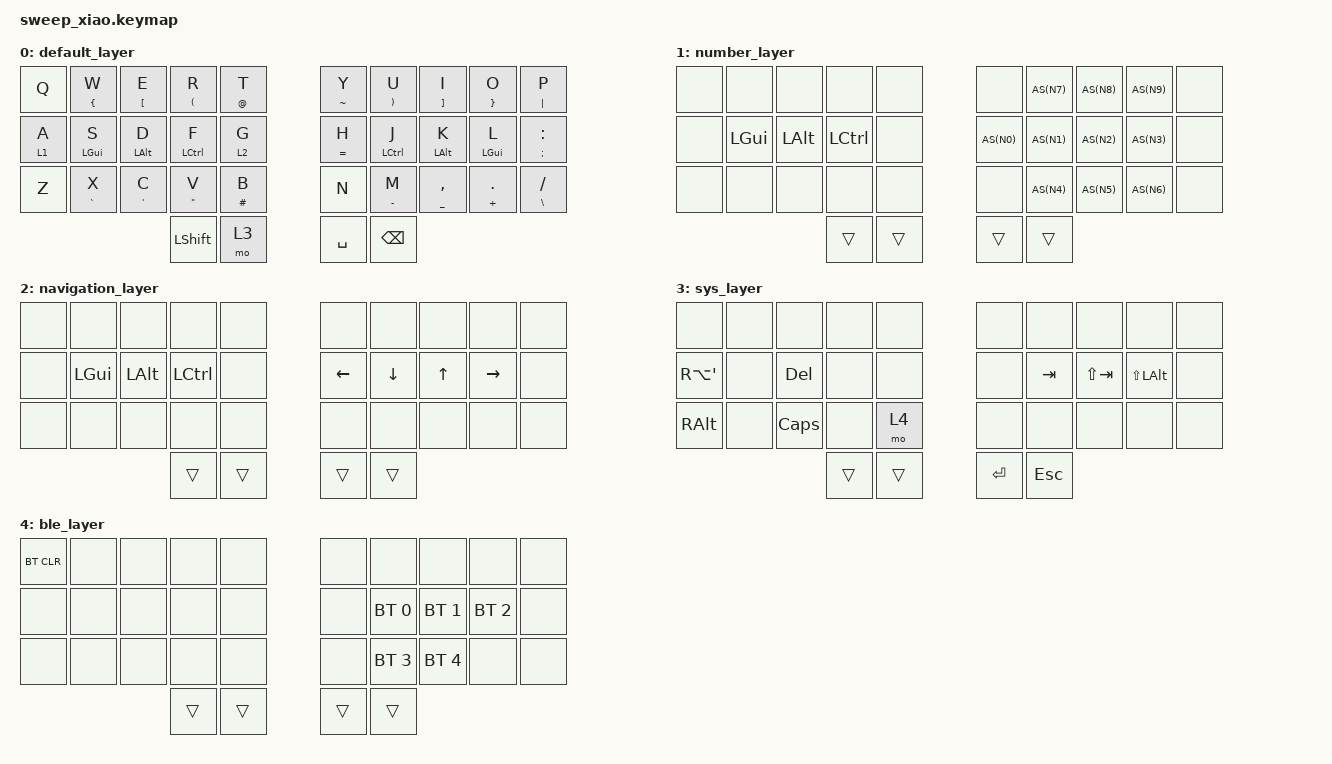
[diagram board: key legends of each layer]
#include <behaviors.dtsi>
#include <dt-bindings/zmk/keys.h>
#include <dt-bindings/zmk/bt.h>

#define AS(key) &ht LS(key) key


/ {
    behaviors {
        ht: hold_tap {
            label = "hold_tap";
            compatible = "zmk,behavior-hold-tap";
            #binding-cells = <2>;
            flavor = "tap-preferred";
            tapping-term-ms = <200>;
            quick-tap-ms = <200>;
            bindings = <&kp>, <&kp>;
        };
        hm: homerow_mods {
            label = "homerow_mods";
            compatible = "zmk,behavior-hold-tap";
            #binding-cells = <2>;
            flavor = "tap-preferred";
            tapping-term-ms = <200>;
            quick-tap-ms = <200>;
            require-prior-idle-ms = <150>;
            bindings = <&kp>, <&kp>;
        };
    };

    keymap {
        compatible = "zmk,keymap";
        default_layer {
            bindings = <
        //╭────────────┬────────────┬────────────┬────────────┬────────────╮   ╭────────────┬────────────┬────────────────┬─────────────┬──────────────╮
           &kp Q        &ht LBRC W   &ht LBKT E   &ht LPAR R   &ht AT T         &ht TILDE Y  &ht RPAR U   &ht RBKT I       &ht RBRC O    &ht PIPE P
        //├────────────┼────────────┼────────────┼────────────┼────────────┤   ├────────────┼────────────┼────────────────┼─────────────┼──────────────┤
           &lt 1 A      &hm LGUI S   &hm LALT D   &hm LCTRL F  &lt 2 G          &ht EQUAL H  &hm LCTRL J  &hm LALT K       &hm LGUI L    &ht SEMI COLON
        //├────────────┼────────────┼────────────┼────────────┼────────────┤   ├────────────┼────────────┼────────────────┼─────────────┼──────────────┤
           &kp Z        &ht GRAVE X  &ht SQT C    &ht DQT V    &ht HASH B       &kp N        &ht MINUS M  &ht UNDER COMMA  &ht PLUS DOT  &ht BSLH FSLH
        //╰────────────┴────────────┴────────────┼────────────┼────────────┤   ├────────────┼────────────┼────────────────┴─────────────┴──────────────╯
                                                  &kp LSHFT    &mo 3            &kp SPACE    &kp BSPC
        //                                       ╰────────────┴────────────╯   ╰────────────┴────────────╯
            >;
        };

        number_layer {
            bindings = <
        //╭────────────┬────────────┬────────────┬────────────┬────────────╮   ╭────────────┬────────────┬────────────┬────────────┬────────────╮
           &none        &none        &none        &none        &none            &none        AS(N7)       AS(N8)       AS(N9)       &none
        //├────────────┼────────────┼────────────┼────────────┼────────────┤   ├────────────┼────────────┼────────────┼────────────┼────────────┤
           &none        &kp LGUI     &kp LALT     &kp LCTRL    &none            AS(N0)       AS(N1)       AS(N2)       AS(N3)       &none
        //├────────────┼────────────┼────────────┼────────────┼────────────┤   ├────────────┼────────────┼────────────┼────────────┼────────────┤
           &none        &none        &none        &none        &none            &none        AS(N4)       AS(N5)       AS(N6)       &none
        //╰────────────┴────────────┴────────────┼────────────┼────────────┤   ├────────────┼────────────┼────────────┴────────────┴────────────╯
                                                  &trans       &trans           &trans       &trans
        //                                       ╰────────────┴────────────╯   ╰────────────┴────────────╯
            >;
        };

        navigation_layer {
            bindings = <
        //╭────────────┬────────────┬────────────┬────────────┬────────────╮   ╭────────────┬────────────┬────────────┬────────────┬────────────╮
           &none        &none        &none        &none        &none            &none        &none        &none        &none        &none
        //├────────────┼────────────┼────────────┼────────────┼────────────┤   ├────────────┼────────────┼────────────┼────────────┼────────────┤
           &none        &kp LGUI     &kp LALT     &kp LCTRL    &none            &kp LEFT     &kp DOWN     &kp UP       &kp RIGHT    &none
        //├────────────┼────────────┼────────────┼────────────┼────────────┤   ├────────────┼────────────┼────────────┼────────────┼────────────┤
           &none        &none        &none        &none        &none            &none        &none        &none        &none        &none
        //╰────────────┴────────────┴────────────┼────────────┼────────────┤   ├────────────┼────────────┼────────────┴────────────┴────────────╯
                                                  &trans       &trans           &trans       &trans
        //                                       ╰────────────┴────────────╯   ╰────────────┴────────────╯
            >;
        };

        sys_layer {
            bindings = <
        //╭────────────┬────────────┬────────────┬────────────┬────────────╮   ╭────────────┬────────────┬────────────┬────────────┬────────────╮
           &none        &none        &none        &none        &none            &none        &none        &none        &none        &none
        //├────────────┼────────────┼────────────┼────────────┼────────────┤   ├────────────┼────────────┼────────────┼────────────┼────────────┤
           &kp RA(SQT)  &none        &kp DEL      &none        &none            &none        &kp TAB      &kp LS(TAB)  &kp LS(LALT) &none
        //├────────────┼────────────┼────────────┼────────────┼────────────┤   ├────────────┼────────────┼────────────┼────────────┼────────────┤
           &kp RALT     &none        &kp CAPS     &none        &mo 4            &none        &none        &none        &none        &none
        //╰────────────┴────────────┴────────────┼────────────┼────────────┤   ├────────────┼────────────┼────────────┴────────────┴────────────╯
                                                  &trans       &trans           &kp RETURN   &kp ESC
        //                                       ╰────────────┴────────────╯   ╰────────────┴────────────╯
            >;
        };

        ble_layer {
            bindings = <
        //╭────────────┬────────────┬────────────┬────────────┬────────────╮   ╭────────────┬────────────┬────────────┬────────────┬────────────╮
           &bt BT_CLR   &none        &none        &none        &none            &none        &none        &none        &none        &none
        //├────────────┼────────────┼────────────┼────────────┼────────────┤   ├────────────┼────────────┼────────────┼────────────┼────────────┤
           &none        &none        &none        &none        &none            &none        &bt BT_SEL 0 &bt BT_SEL 1 &bt BT_SEL 2 &none
        //├────────────┼────────────┼────────────┼────────────┼────────────┤   ├────────────┼────────────┼────────────┼────────────┼────────────┤
           &none        &none        &none        &none        &none            &none        &bt BT_SEL 3 &bt BT_SEL 4 &none        &none
        //╰────────────┴────────────┴────────────┼────────────┼────────────┤   ├────────────┼────────────┼────────────┴────────────┴────────────╯
                                                  &trans       &trans           &trans       &trans
        //                                       ╰────────────┴────────────╯   ╰────────────┴────────────╯
            >;
        };
    };
};
